# CS_356.0 register map
Vendor: Texas Instruments
Peripheral module from a debugger description file (folder MSP432).
Registers are 32-bit, read-write, no defined reset value unless marked. A register's access mark holds for its fields unless they carry their own. Offsets are as the file gives them; lines under a group give offsets from that group; [hi:lo] are bit positions; {n}, {i} and the like mark numbered series; 'fields as' and 'values as' point back to an identical list; <NAME> marks a mode.

## CS
0x00 CSKEY — Key Register
  [15:0] CSKEY — Write xxxx_695Ah to unlock
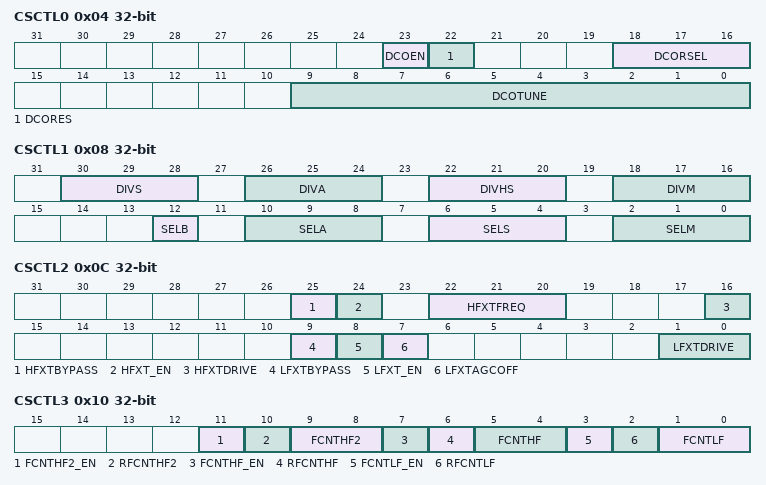
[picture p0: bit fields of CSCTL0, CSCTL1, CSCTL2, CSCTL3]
0x04 CSCTL0 — Control 0 Register
  [23] DCOEN — Enables the DCO oscillator
    0=OFF (DCO is on if it is used as a source for MCLK, HSMCLK , or SMCLK and clock is requested, otherwise it is disabled.); 1=ON (DCO is on)
  [22] DCORES — Enables the DCO external resistor mode
    0=INTERNAL (Internal resistor mode); 1=EXTERNAL (External resistor mode)
  [18:16] DCORSEL — DCO frequency range select
    0=Nominal DCO Frequency Range (MHz): 1 to 2; 1=Nominal DCO Frequency Range (MHz): 2 to 4; 2=Nominal DCO Frequency Range (MHz): 4 to 8; 3=Nominal DCO Frequency Range (MHz): 8 to 16; 4=Nominal DCO Frequency Range (MHz): 16 to 32; 5=Nominal DCO Frequency Range (MHz): 32 to 64
  [9:0] DCOTUNE — DCO frequency tuning select
0x08 CSCTL1 — Control 1 Register
  [30:28] DIVS — SMCLK source divider
    0=f(SMCLK)/1; 1=f(SMCLK)/2; 2=f(SMCLK)/4; 3=f(SMCLK)/8; 4=f(SMCLK)/16; 5=f(SMCLK)/32; 6=f(SMCLK)/64; 7=f(SMCLK)/128
  [26:24] DIVA — ACLK source divider
    0=f(ACLK)/1; 1=f(ACLK)/2; 2=f(ACLK)/4; 3=f(ACLK)/8; 4=f(ACLK)/16; 5=f(ACLK)/32; 6=f(ACLK)/64; 7=f(ACLK)/128
  [22:20] DIVHS — HSMCLK source divider
    0=f(HSMCLK)/1; 1=f(HSMCLK)/2; 2=f(HSMCLK)/4; 3=f(HSMCLK)/8; 4=f(HSMCLK)/16; 5=f(HSMCLK)/32; 6=f(HSMCLK)/64; 7=f(HSMCLK)/128
  [18:16] DIVM — MCLK source divider
    0=f(MCLK)/1; 1=f(MCLK)/2; 2=f(MCLK)/4; 3=f(MCLK)/8; 4=f(MCLK)/16; 5=f(MCLK)/32; 6=f(MCLK)/64; 7=f(MCLK)/128
  [12] SELB — Selects the BCLK source
    0=LFXTCLK; 1=REFOCLK
  [10:8] SELA — Selects the ACLK source
    0=LFXTCLK (when LFXT available, otherwise REFOCLK); 1=VLOCLK; 2=REFOCLK
  [6:4] SELS — Selects the SMCLK and HSMCLK source
    0=LFXTCLK (when LFXT available, otherwise REFOCLK); 1=VLOCLK; 2=REFOCLK; 3=DCOCLK; 4=MODOSC; 5=HFXTCLK (when HFXT available, otherwise DCOCLK)
  [2:0] SELM — Selects the MCLK source
    values as SELS
0x0C CSCTL2 — Control 2 Register
  [25] HFXTBYPASS — HFXT bypass select
    0=HFXT sourced by external crystal; 1=HFXT sourced by external square wave
  [24] HFXT_EN — Turns on the HFXT oscillator regardless if used as a clock resource
    0=OFF (HFXT is on if it is used as a source for MCLK, HSMCLK , or SMCLK and is selected via the port selection and not in bypass mode of operation.); 1=ON (HFXT is on if HFXT is selected via the port selection and HFXT is not in bypass mode of operation.)
  [22:20] HFXTFREQ — HFXT frequency selection
    0=1 MHz to 4 MHz; 1=4 MHz to 8 MHz; 2=8 MHz to 16 MHz; 3=16 MHz to 24 MHz; 4=24 MHz to 32 MHz; 5=32 MHz to 40 MHz; 6=40 MHz to 48 MHz; 7=Reserved for future use
  [16] HFXTDRIVE — HFXT oscillator drive selection
    0=To be used for HFXTFREQ setting 000b; 1=To be used for HFXTFREQ settings 001b to 110b
  [9] LFXTBYPASS — LFXT bypass select
    0=OFF (LFXT sourced by external crystal.); 1=ON (LFXT sourced by external square wave.)
  [8] LFXT_EN — Turns on the LFXT oscillator regardless if used as a clock resource
    0=OFF (LFXT is on if it is used as a source for ACLK, MCLK, HSMCLK , or SMCLK and is selected via the port selection and not in bypass mode of operation.); 1=ON (LFXT is on if LFXT is selected via the port selection and LFXT is not in bypass mode of operation.)
  [7] LFXTAGCOFF — Disables the automatic gain control of the LFXT crystal
    0=AGC enabled; 1=AGC disabled
  [1:0] LFXTDRIVE — LFXT oscillator current can be adjusted to its drive needs
    0=Lowest drive strength and current consumption LFXT oscillator; 1=Increased drive strength LFXT oscillator; 2=Increased drive strength LFXT oscillator; 3=Maximum drive strength and maximum current consumption LFXT oscillator
0x10 CSCTL3 — Control 3 Register
  [11] FCNTHF2_EN — Enable start fault counter for HFXT2
    0=OFF (Startup fault counter disabled. Counter is cleared.); 1=ON (Startup fault counter enabled.)
  [10] RFCNTHF2 — Reset start fault counter for HFXT2
    0=Not applicable. Always reads as zero due to self clearing.; 1=RESTART (Restarts the counter immediately.)
  [9:8] FCNTHF2 — Start flag counter for HFXT2
    0=2048 cycles; 1=4096 cycles; 2=8192 cycles; 3=16384 cycles
  [7] FCNTHF_EN — Enable start fault counter for HFXT
    values as FCNTHF2_EN
  [6] RFCNTHF — Reset start fault counter for HFXT
    values as RFCNTHF2
  [5:4] FCNTHF — Start flag counter for HFXT
    0=2048 cycles; 1=4096 cycles; 2=8192 cycles; 3=16384 cycles
  [3] FCNTLF_EN — Enable start fault counter for LFXT
    values as FCNTHF2_EN
  [2] RFCNTLF — Reset start fault counter for LFXT
    values as RFCNTHF2
  [1:0] FCNTLF — Start flag counter for LFXT
    0=4096 cycles; 1=8192 cycles; 2=16384 cycles; 3=32768 cycles
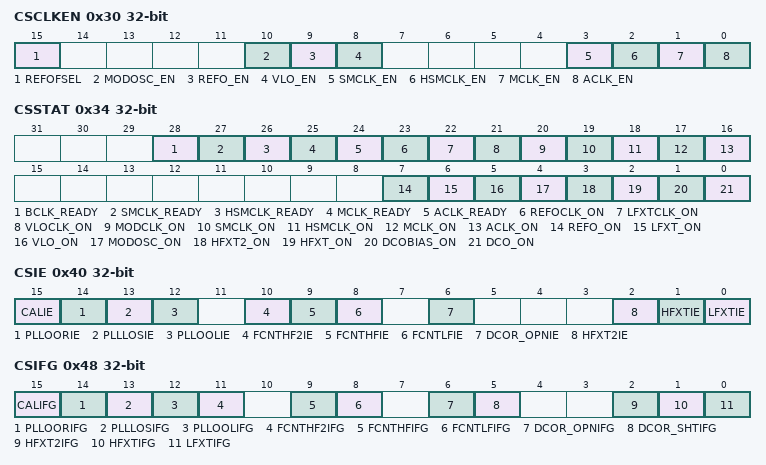
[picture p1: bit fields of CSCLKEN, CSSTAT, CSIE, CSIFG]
0x30 CSCLKEN — Clock Enable Register
  [15] REFOFSEL — Selects REFO nominal frequency
    0=32 kHz; 1=128 kHz
  [10] MODOSC_EN — Turns on the MODOSC oscillator
    0=OFF (MODOSC is on only if it is used as a source for ACLK, MCLK, HSMCLK or SMCLK); 1=ON (MODOSC is on)
  [9] REFO_EN — Turns on the REFO oscillator
    0=OFF (REFO is on only if it is used as a source for ACLK, MCLK, HSMCLK or SMCLK); 1=ON (REFO is on)
  [8] VLO_EN — Turns on the VLO oscillator
    0=OFF (VLO is on only if it is used as a source for ACLK, MCLK, HSMCLK or SMCLK.); 1=ON (VLO is on)
  [3] SMCLK_EN — SMCLK system clock conditional request enable
    0=DISABLE (SMCLK disabled regardless of conditional clock requests.); 1=ENABLE (SMCLK enabled based on any conditional clock requests)
  [2] HSMCLK_EN — HSMCLK system clock conditional request enable
    0=DISABLE (HSMCLK disabled regardless of conditional clock requests); 1=ENABLE (HSMCLK enabled based on any conditional clock requests)
  [1] MCLK_EN — MCLK system clock conditional request enable
    0=DISABLE (MCLK disabled regardless of conditional clock requests); 1=ENABLE (MCLK enabled based on any conditional clock requests)
  [0] ACLK_EN — ACLK system clock conditional request enable
    0=DISABLE (ACLK disabled regardless of conditional clock requests); 1=ENABLE (ACLK enabled based on any conditional clock requests)
0x34 CSSTAT ro — Status Register
  [28] BCLK_READY — BCLK Ready status
    0=NOT_READY; 1=READY
  [27] SMCLK_READY — SMCLK Ready status
    0=NOT_READY; 1=READY
  [26] HSMCLK_READY — HSMCLK Ready status
    0=NOT_READY; 1=READY
  [25] MCLK_READY — MCLK Ready status
    0=NOT_READY; 1=READY
  [24] ACLK_READY — ACLK Ready status
    0=NOT_READY; 1=READY
  [23] REFOCLK_ON — REFOCLK system clock status
    0=INACTIVE; 1=ACTIVE
  [22] LFXTCLK_ON — LFXTCLK system clock status
    0=INACTIVE; 1=ACTIVE
  [21] VLOCLK_ON — VLOCLK system clock status
    0=INACTIVE; 1=ACTIVE
  [20] MODCLK_ON — MODCLK system clock status
    0=INACTIVE; 1=ACTIVE
  [19] SMCLK_ON — SMCLK system clock status
    0=INACTIVE; 1=ACTIVE
  [18] HSMCLK_ON — HSMCLK system clock status
    0=INACTIVE; 1=ACTIVE
  [17] MCLK_ON — MCLK system clock status
    0=INACTIVE; 1=ACTIVE
  [16] ACLK_ON — ACLK system clock status
    0=INACTIVE; 1=ACTIVE
  [7] REFO_ON — REFO status
    0=INACTIVE; 1=ACTIVE
  [6] LFXT_ON — LFXT status
    0=INACTIVE; 1=ACTIVE
  [5] VLO_ON — VLO status
    0=INACTIVE; 1=ACTIVE
  [4] MODOSC_ON — MODOSC status
    0=INACTIVE; 1=ACTIVE
  [3] HFXT2_ON — HFXT2 status
    0=INACTIVE; 1=ACTIVE
  [2] HFXT_ON — HFXT status
    0=INACTIVE; 1=ACTIVE
  [1] DCOBIAS_ON — DCO bias status
    0=INACTIVE; 1=ACTIVE
  [0] DCO_ON — DCO status
    0=INACTIVE; 1=ACTIVE
0x40 CSIE — Interrupt Enable Register
  [all] fields
    0=DISABLE (Interrupt disabled); 1=ENABLE (Interrupt enabled)
  [15] CALIE — REFCNT period counter interrupt enable
  [14] PLLOORIE — PLL out-of-range interrupt enable
  [13] PLLLOSIE — PLL loss-of-signal interrupt enable
  [12] PLLOOLIE — PLL out-of-lock interrupt enable
  [10] FCNTHF2IE — Start fault counter interrupt enable HFXT2
  [9] FCNTHFIE — Start fault counter interrupt enable HFXT
  [8] FCNTLFIE — Start fault counter interrupt enable LFXT
  [6] DCOR_OPNIE — DCO external resistor open circuit fault flag interrupt enable.
  [2] HFXT2IE — HFXT2 oscillator fault flag interrupt enable
  [1] HFXTIE — HFXT oscillator fault flag interrupt enable
  [0] LFXTIE — LFXT oscillator fault flag interrupt enable
0x48 CSIFG ro — Interrupt Flag Register
  [15] CALIFG — REFCNT period counter expired
    0=REFCNT period counter not expired; 1=REFCNT period counter expired
  [14] PLLOORIFG — PLL out-of-range interrupt flag
    0=No interrupt pending; 1=Interrupt pending
  [13] PLLLOSIFG — PLL loss-of-signal interrupt flag
    0=No interrupt pending; 1=Interrupt pending
  [12] PLLOOLIFG — PLL out-of-lock interrupt flag
    0=No interrupt pending; 1=Interrupt pending
  [11] FCNTHF2IFG — Start fault counter interrupt flag HFXT2
    0=Start counter not expired; 1=Start counter expired
  [9] FCNTHFIFG — Start fault counter interrupt flag HFXT
    0=Start counter not expired; 1=Start counter expired
  [8] FCNTLFIFG — Start fault counter interrupt flag LFXT
    0=Start counter not expired; 1=Start counter expired
  [6] DCOR_OPNIFG — DCO external resistor open circuit fault flag.
    0=DCO external resistor present; 1=DCO external resistor open circuit fault
  [5] DCOR_SHTIFG — DCO external resistor short circuit fault flag.
    0=DCO external resistor present; 1=DCO external resistor short circuit fault
  [2] HFXT2IFG — HFXT2 oscillator fault flag
    0=No fault condition occurred after the last reset; 1=HFXT2 fault. A HFXT2 fault occurred after the last reset
  [1] HFXTIFG — HFXT oscillator fault flag
    0=No fault condition occurred after the last reset; 1=HFXT fault. A HFXT fault occurred after the last reset
  [0] LFXTIFG — LFXT oscillator fault flag
    0=No fault condition occurred after the last reset; 1=LFXT fault. A LFXT fault occurred after the last reset
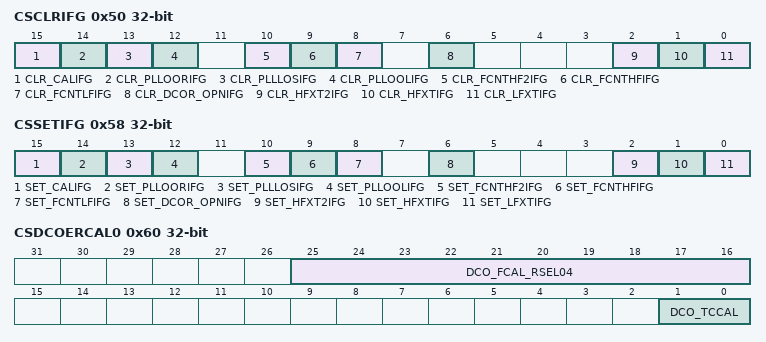
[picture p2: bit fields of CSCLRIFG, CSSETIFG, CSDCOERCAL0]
0x50 CSCLRIFG — Clear Interrupt Flag Register
  [all] fields
    0=No effect; 1=Clear pending interrupt flag
  [15] CLR_CALIFG — REFCNT period counter clear interrupt flag
  [14] CLR_PLLOORIFG — PLL out-of-range clear interrupt flag
  [13] CLR_PLLLOSIFG — PLL loss-of-signal clear interrupt flag
  [12] CLR_PLLOOLIFG — PLL out-of-lock clear interrupt flag
  [10] CLR_FCNTHF2IFG — Start fault counter clear interrupt flag HFXT2
  [9] CLR_FCNTHFIFG — Start fault counter clear interrupt flag HFXT
  [8] CLR_FCNTLFIFG — Start fault counter clear interrupt flag LFXT
  [6] CLR_DCOR_OPNIFG — Clear DCO external resistor open circuit fault interrupt flag.
  [2] CLR_HFXT2IFG — Clear HFXT2 oscillator fault interrupt flag
  [1] CLR_HFXTIFG — Clear HFXT oscillator fault interrupt flag
  [0] CLR_LFXTIFG — Clear LFXT oscillator fault interrupt flag
0x58 CSSETIFG — Set Interrupt Flag Register
  [all] fields
    0=No effect; 1=Set pending interrupt flag
  [15] SET_CALIFG — REFCNT period counter set interrupt flag
  [14] SET_PLLOORIFG — PLL out-of-range set interrupt flag
  [13] SET_PLLLOSIFG — PLL loss-of-signal set interrupt flag
  [12] SET_PLLOOLIFG — PLL out-of-lock set interrupt flag
  [10] SET_FCNTHF2IFG — Start fault counter set interrupt flag HFXT2
  [9] SET_FCNTHFIFG — Start fault counter set interrupt flag HFXT
  [8] SET_FCNTLFIFG — Start fault counter set interrupt flag LFXT
  [6] SET_DCOR_OPNIFG — Set DCO external resistor open circuit fault interrupt flag.
  [2] SET_HFXT2IFG — Set HFXT2 oscillator fault interrupt flag
  [1] SET_HFXTIFG — Set HFXT oscillator fault interrupt flag
  [0] SET_LFXTIFG — Set LFXT oscillator fault interrupt flag
0x60 CSDCOERCAL0 — DCO External Resistor Cailbration 0 Register
  [25:16] DCO_FCAL_RSEL04 — DCO frequency calibration for DCO frequency range (DCORSEL) 0 to 4.
  [1:0] DCO_TCCAL — DCO Temperature compensation calibration
0x64 CSDCOERCAL1 — DCO External Resistor Calibration 1 Register
  [9:0] DCO_FCAL_RSEL5 — DCO frequency calibration for DCO frequency range (DCORSEL) 5.
